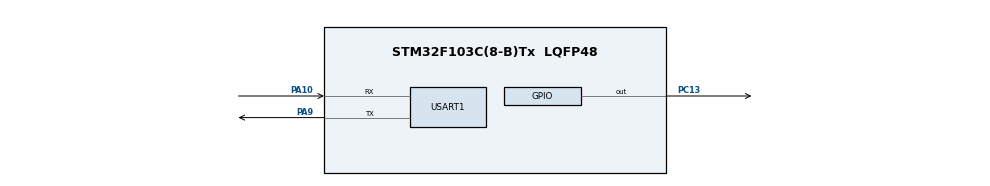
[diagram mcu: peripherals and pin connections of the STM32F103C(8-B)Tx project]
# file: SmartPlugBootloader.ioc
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Mcu.Family=STM32F1
Mcu.Name=STM32F103C(8-B)Tx
Mcu.Package=LQFP48
NVIC.PriorityGroup=NVIC_PRIORITYGROUP_4
PA10.Mode=Asynchronous
PA10.Signal=USART1_RX
PA13.Mode=Serial_Wire
PA13.Signal=SYS_JTMS-SWDIO
PA14.Mode=Serial_Wire
PA14.Signal=SYS_JTCK-SWCLK
PA9.Mode=Asynchronous
PA9.Signal=USART1_TX
PC13-TAMPER-RTC.Signal=GPIO_Output
ProjectManager.HeapSize=0x200
ProjectManager.StackSize=0x400
ProjectManager.TargetToolchain=STM32CubeIDE
RCC.APB1Freq_Value=8000000
RCC.APB2Freq_Value=8000000
USART1.VirtualMode=VM_ASYNC
board=custom

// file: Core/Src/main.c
/* USER CODE BEGIN Header */
/**
  ******************************************************************************
  * @file           : main.c
  * @brief          : Main program body
  ******************************************************************************
  * @attention
  *
  * <h2><center>&copy; Copyright (c) 2020 STMicroelectronics.
  * All rights reserved.</center></h2>
  *
  * This software component is licensed by ST under BSD 3-Clause license,
  * the "License"; You may not use this file except in compliance with the
  * License. You may obtain a copy of the License at:
  *                        opensource.org/licenses/BSD-3-Clause
  *
  ******************************************************************************
  */
/* USER CODE END Header */
#include "main.h"
#include "usart.h"
#include "gpio.h"

/* USER CODE BEGIN Includes */
#include <stdio.h>
#include <stdlib.h>
#include<string.h>
#include "stm32f1xx_hal.h"
#include "flash.h"
/* USER CODE END Includes */

/* USER CODE BEGIN PTD */
/* Function pointer for jumping to user application. */
typedef void (*fnc_ptr)(void);
/* USER CODE END PTD */

void SystemClock_Config(void);

/* Status report for the functions. */

/* USER CODE BEGIN 0 */
typedef enum {
  UPGRADE_STATE_START = 0x00u,
  UPGRADE_STATE_PROC = 0x01u,
  UPGRADE_STATE_END = 0x02u,
} upgrade_state;
/* USER CODE END 0 */

int main(void)
{

  /* MCU Configuration--------------------------------------------------------*/

  /* Reset of all peripherals, Initializes the Flash interface and the Systick. */
  HAL_Init();

  /* Configure the system clock */
  SystemClock_Config();

  /* Initialize all configured peripherals */
  MX_GPIO_Init();
  MX_USART1_UART_Init();
  /* USER CODE BEGIN 2 */
  printf("Firmware Version...%s,%s%s\r\n", FW_VERSION, __DATE__, __TIME__);
  /* USER CODE END 2 */

  /* Infinite loop */
  /* USER CODE BEGIN WHILE */
  // [UART]
  uint16_t data_length = 0;
  uint8_t *uart_receive_data = NULL;
  uart_receive_data = (uint8_t *)malloc(sizeof(uint8_t)*UART_RECEIVE_SIZE);
  // [FLASH]
  uint32_t upgrade_id = UPGRADE_ID;
  uint32_t upgrade_id_checker = 0;
  uint32_t upgrade_chksum = 0;
  uint32_t receive_chksum = 0;
  uint32_t total_fw_length = 0;
  // [MAIN LOOP]
  upgrade_state upgrade_status = UPGRADE_STATE_START;

  while (1)
  {
	  upgrade_id_checker = (uint32_t)(*(uint32_t *)(FLASH_UPGRADEINFO_START_ADDRESS));
#ifdef _DEBUG_FLOW
	  DEBUG_INFO("upgrade_id_checker = 0x%08x\r\n", upgrade_id_checker);
#endif
	  if (upgrade_id_checker == UPGRADE_ID)
	  {
		  printf("READY_TO_UPGRADE\r\n");
		  flash_erase(FLASH_APP2_START_ADDRESS, FLASH_APP2_PAGES);
		  flash_erase(FLASH_UPGRADEINFO_START_ADDRESS, FLASH_UPGRADEINFO_PAGES);
		  upgrade_chksum = 0;
		  total_fw_length = 0;

		  while(1)
		  {
			  if (upgrade_status == UPGRADE_STATE_START)
			  {
				  memset(uart_receive_data, '\0', sizeof(uint8_t)*UART_RECEIVE_SIZE);
				  HAL_UART_Receive(&huart1, uart_receive_data, UPGRADE_STATE_START_LENGTH, UART_TIMEOUT);
#ifdef _DEBUG_FLOW
				  DEBUG_INFO("[UPGRADE_STATE_START] uart_receive_data %s\r\n", (char *)uart_receive_data);
#endif
				  if (uart_receive_data[0] == 'F' && uart_receive_data[1] == 'W' && uart_receive_data[2] == 'U' && uart_receive_data[3] == 'G' && \
					  uart_receive_data[4] == '\r' && uart_receive_data[5] == '\n')
				  {
					  printf("OK\r\n");
					  upgrade_status = UPGRADE_STATE_PROC;
				  }
				  else
				  {
					  printf("FAIL\r\n");
					  flash_jump_to_app();
				  }
			  }
			  else if (upgrade_status == UPGRADE_STATE_PROC)
			  {
				  memset(uart_receive_data, '\0', sizeof(uint8_t)*UART_RECEIVE_SIZE);
				  HAL_UART_Receive(&huart1, uart_receive_data, UPGRADE_STATE_PROC_LENGTH, UART_TIMEOUT);
				  data_length = ((((uint16_t)uart_receive_data[0])<<8) + ((uint16_t)uart_receive_data[1]));
#ifdef _DEBUG_FLOW
				  DEBUG_INFO("[UPGRADE_STATE_PROC] data_length = %d\r\n", (int)data_length);
#endif
				  if (data_length > (UPGRADE_STATE_PROC_LENGTH - 4) || uart_receive_data[(UPGRADE_STATE_PROC_LENGTH - 2)] != '\r' || uart_receive_data[(UPGRADE_STATE_PROC_LENGTH - 1)] != '\n')
				  {
					  printf("FAIL\r\n");
					  flash_jump_to_app();
				  }
				  else if (data_length != 0)
				  {
					  for (int i=2; i<(data_length+2); i++)
					  {
						  upgrade_chksum += uart_receive_data[i];
					  }

					  if (data_length < (UPGRADE_STATE_PROC_LENGTH - 4))
					  {
						  upgrade_status = UPGRADE_STATE_END;
						  for (int i=(data_length+2); i<UPGRADE_STATE_PROC_LENGTH; i++)
						  {
							  uart_receive_data[i] = 0xFF;
						  }
					  }

					  flash_write((FLASH_APP2_START_ADDRESS+total_fw_length), (uint32_t*)&uart_receive_data[2], ((UPGRADE_STATE_PROC_LENGTH - 4)/4));
					  total_fw_length += data_length;
					  printf("OK\r\n");
				  }
				  else if (data_length == 0)
				  {
					  upgrade_status = UPGRADE_STATE_END;
					  printf("OK\r\n");
				  }
			  }
			  else if (upgrade_status == UPGRADE_STATE_END)
			  {
				  memset(uart_receive_data, '\0', sizeof(uint8_t)*UART_RECEIVE_SIZE);
				  HAL_UART_Receive(&huart1, uart_receive_data, UPGRADE_STATE_END_LENGTH, UART_TIMEOUT);
#ifdef _DEBUG_FLOW
				  DEBUG_INFO("[UPGRADE_STATE_END] upgrade_chksum = 0x%08x\r\n", upgrade_chksum);
				  DEBUG_INFO("[UPGRADE_STATE_END] uart_receive_data %s\r\n", (char *)uart_receive_data);
#endif
				  receive_chksum = ((((uint16_t)uart_receive_data[4])<<24) + (((uint16_t)uart_receive_data[5])<<16) + (((uint16_t)uart_receive_data[6])<<8) + ((uint16_t)uart_receive_data[7]));
				  if (uart_receive_data[0] == 'F' && uart_receive_data[1] == 'W' && uart_receive_data[2] == 'E' && uart_receive_data[3] == 'D' && \
					  uart_receive_data[8] == '\r' && uart_receive_data[9] == '\n' && \
					  upgrade_chksum == receive_chksum)
				  {
					  flash_write(FLASH_APP1_START_ADDRESS, (uint32_t *)(FLASH_APP2_START_ADDRESS), (total_fw_length/4));
					  printf("OK\r\n");
#ifdef _DEBUG_FLOW
					  DEBUG_INFO("FLASH_APP1_START_ADDRESS\r\n");
					  for (int i=0; i<(total_fw_length-1); i++)
					  {
						  printf("[%d]0x%x, ", i, *(uint8_t *)(FLASH_APP1_START_ADDRESS+i));
					  }
					  printf("[%d]0x%x\r\n", (total_fw_length-1), *(uint8_t *)(FLASH_APP1_START_ADDRESS+(total_fw_length-1)));
					  DEBUG_INFO("FLASH_APP2_START_ADDRESS\r\n");
					  for (int i=0; i<(total_fw_length-1); i++)
					  {
						  printf("[%d]0x%x, ", i, *(uint8_t *)(FLASH_APP2_START_ADDRESS+i));
					  }
					  printf("[%d]0x%x\r\n", (total_fw_length-1), *(uint8_t *)(FLASH_APP2_START_ADDRESS+(total_fw_length-1)));
					  DEBUG_INFO("#\r\n");
#endif
				  }
				  else
				  {
					  printf("FAIL\r\n");
				  }

				  flash_jump_to_app();
			  }
		  }
	  }
	  else
	  {
		  printf("DONT_NEED_TO_UPGRADE\r\n");
#ifdef _DEBUG_FLOW
		  flash_write(FLASH_UPGRADEINFO_START_ADDRESS, (uint32_t*)&upgrade_id, 1);
#endif
		  flash_jump_to_app();
	  }

    /* USER CODE END WHILE */

    /* USER CODE BEGIN 3 */
	// TIME DELAY
	HAL_Delay(100);
  }
  /* USER CODE END 3 */
}

void SystemClock_Config(void)
{
  RCC_OscInitTypeDef RCC_OscInitStruct = {0};
  RCC_ClkInitTypeDef RCC_ClkInitStruct = {0};

  /** Initializes the RCC Oscillators according to the specified parameters
  * in the RCC_OscInitTypeDef structure.
  */
  RCC_OscInitStruct.OscillatorType = RCC_OSCILLATORTYPE_HSI;
  RCC_OscInitStruct.HSIState = RCC_HSI_ON;
  RCC_OscInitStruct.HSICalibrationValue = RCC_HSICALIBRATION_DEFAULT;
  RCC_OscInitStruct.PLL.PLLState = RCC_PLL_NONE;
  if (HAL_RCC_OscConfig(&RCC_OscInitStruct) != HAL_OK)
  {
    Error_Handler();
  }
  /** Initializes the CPU, AHB and APB buses clocks
  */
  RCC_ClkInitStruct.ClockType = RCC_CLOCKTYPE_HCLK|RCC_CLOCKTYPE_SYSCLK
                              |RCC_CLOCKTYPE_PCLK1|RCC_CLOCKTYPE_PCLK2;
  RCC_ClkInitStruct.SYSCLKSource = RCC_SYSCLKSOURCE_HSI;
  RCC_ClkInitStruct.AHBCLKDivider = RCC_SYSCLK_DIV1;
  RCC_ClkInitStruct.APB1CLKDivider = RCC_HCLK_DIV1;
  RCC_ClkInitStruct.APB2CLKDivider = RCC_HCLK_DIV1;

  if (HAL_RCC_ClockConfig(&RCC_ClkInitStruct, FLASH_LATENCY_0) != HAL_OK)
  {
    Error_Handler();
  }
}

void Error_Handler(void)
{
  __disable_irq();
  while (1)
  {
  }
}

/************************ (C) COPYRIGHT STMicroelectronics *****END OF FILE****/
